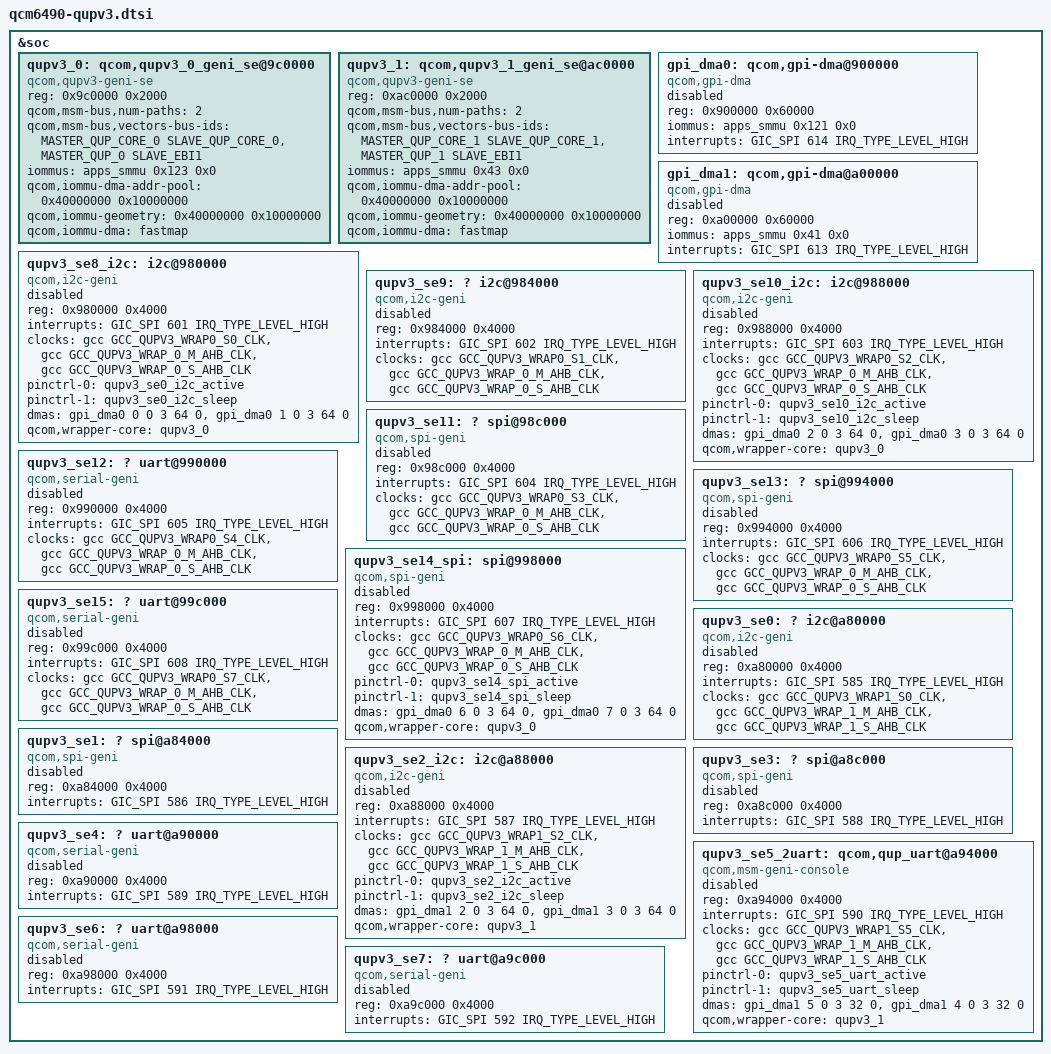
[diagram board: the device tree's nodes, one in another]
&soc {
	/* QUPv3 Serial Engine Instances mapping:
	 * - QUPv3_1 wrapper covers SE0..SE7
	 * - QUPv3_0 wrapper covers SE8..SE15
	 */

	/* QUPv3_0 wrapper instance (Serial Engines 8-15) */
	qupv3_0: qcom,qupv3_0_geni_se@9c0000 {
		compatible = "qcom,qupv3-geni-se";
		reg = <0x9c0000 0x2000>;
		qcom,msm-bus,num-paths = <2>;
		qcom,msm-bus,vectors-bus-ids =
			<MASTER_QUP_CORE_0 SLAVE_QUP_CORE_0>,
			<MASTER_QUP_0       SLAVE_EBI1>;
		iommus = <&apps_smmu 0x123 0x0>;
		qcom,iommu-dma-addr-pool = <0x40000000 0x10000000>;
		qcom,iommu-geometry    = <0x40000000 0x10000000>;
		qcom,iommu-dma         = "fastmap";
		status = "ok";
	};

	/* QUPv3_1 wrapper instance (Serial Engines 0-7) */
	qupv3_1: qcom,qupv3_1_geni_se@ac0000 {
		compatible = "qcom,qupv3-geni-se";
		reg = <0xac0000 0x2000>;
		qcom,msm-bus,num-paths = <2>;
		qcom,msm-bus,vectors-bus-ids =
			<MASTER_QUP_CORE_1 SLAVE_QUP_CORE_1>,
			<MASTER_QUP_1       SLAVE_EBI1>;
		iommus = <&apps_smmu 0x43 0x0>;
		qcom,iommu-dma-addr-pool = <0x40000000 0x10000000>;
		qcom,iommu-geometry    = <0x40000000 0x10000000>;
		qcom,iommu-dma         = "fastmap";
		status = "ok";
	};

	/* GPI DMA controllers for QUP (shared DMA engines) */
	gpi_dma0: qcom,gpi-dma@900000 {
		compatible = "qcom,gpi-dma";
		#dma-cells = <5>;
		reg = <0x900000 0x60000>;
		reg-names = "gpi-top";
		iommus = <&apps_smmu 0x121 0x0>;
		interrupts = <GIC_SPI 614 IRQ_TYPE_LEVEL_HIGH>;
		interrupt-names = "gpi";
		status = "disabled";
	};

	gpi_dma1: qcom,gpi-dma@a00000 {
		compatible = "qcom,gpi-dma";
		#dma-cells = <5>;
		reg = <0xa00000 0x60000>;
		reg-names = "gpi-top";
		iommus = <&apps_smmu 0x41 0x0>;
		interrupts = <GIC_SPI 613 IRQ_TYPE_LEVEL_HIGH>;
		interrupt-names = "gpi";
		status = "disabled";
	};

	/* QUPv3 Serial Engines (SE0..SE15) child nodes */
	qupv3_se8_i2c: i2c@980000 {
		compatible = "qcom,i2c-geni";
		reg = <0x980000 0x4000>;
		#address-cells = <1>;
		#size-cells = <0>;
		interrupts = <GIC_SPI 601 IRQ_TYPE_LEVEL_HIGH>;
		clock-names = "se-clk", "m-ahb", "s-ahb";
		clocks = <&gcc GCC_QUPV3_WRAP0_S0_CLK>,
			 <&gcc GCC_QUPV3_WRAP_0_M_AHB_CLK>,
			 <&gcc GCC_QUPV3_WRAP_0_S_AHB_CLK>;
		pinctrl-names = "default", "sleep";
		pinctrl-0 = <&qupv3_se0_i2c_active>;
		pinctrl-1 = <&qupv3_se0_i2c_sleep>;
		dmas = <&gpi_dma0 0 0 3 64 0>,
		       <&gpi_dma0 1 0 3 64 0>;
		dma-names = "tx", "rx";
		qcom,wrapper-core = <&qupv3_0>;
		status = "disabled";
	};

	qupv3_se9:? i2c@984000 {
		compatible = "qcom,i2c-geni";
		reg = <0x984000 0x4000>;
		#address-cells = <1>; #size-cells = <0>;
		interrupts = <GIC_SPI 602 IRQ_TYPE_LEVEL_HIGH>;
		clock-names = "se-clk", "m-ahb", "s-ahb";
		clocks = <&gcc GCC_QUPV3_WRAP0_S1_CLK>,
			 <&gcc GCC_QUPV3_WRAP_0_M_AHB_CLK>,
			 <&gcc GCC_QUPV3_WRAP_0_S_AHB_CLK>;
		... /* (pinctrl, DMA and wrapper-core similar to above) */
		status = "disabled";
	};

	qupv3_se10_i2c: i2c@988000 {
		compatible = "qcom,i2c-geni";
		reg = <0x988000 0x4000>;
		#address-cells = <1>; #size-cells = <0>;
		interrupts = <GIC_SPI 603 IRQ_TYPE_LEVEL_HIGH>;
		clock-names = "se-clk", "m-ahb", "s-ahb";
		clocks = <&gcc GCC_QUPV3_WRAP0_S2_CLK>,
			 <&gcc GCC_QUPV3_WRAP_0_M_AHB_CLK>,
			 <&gcc GCC_QUPV3_WRAP_0_S_AHB_CLK>;
		pinctrl-names = "default", "sleep";
		pinctrl-0 = <&qupv3_se10_i2c_active>;
		pinctrl-1 = <&qupv3_se10_i2c_sleep>;
		dmas = <&gpi_dma0 2 0 3 64 0>,
		       <&gpi_dma0 3 0 3 64 0>;
		dma-names = "tx", "rx";
		qcom,wrapper-core = <&qupv3_0>;
		status = "disabled";
	};

	qupv3_se11:? spi@98c000 {
		compatible = "qcom,spi-geni";
		reg = <0x98c000 0x4000>;
		#address-cells = <1>; #size-cells = <0>;
		interrupts = <GIC_SPI 604 IRQ_TYPE_LEVEL_HIGH>;
		clock-names = "se-clk", "m-ahb", "s-ahb";
		clocks = <&gcc GCC_QUPV3_WRAP0_S3_CLK>,
			 <&gcc GCC_QUPV3_WRAP_0_M_AHB_CLK>,
			 <&gcc GCC_QUPV3_WRAP_0_S_AHB_CLK>;
		... /* (pinctrl, DMA, wrapper-core properties) */
		status = "disabled";
	};

	qupv3_se12:? uart@990000 {
		compatible = "qcom,serial-geni";
		reg = <0x990000 0x4000>;
		#address-cells = <1>; #size-cells = <0>;
		interrupts = <GIC_SPI 605 IRQ_TYPE_LEVEL_HIGH>;
		clock-names = "se-clk", "m-ahb", "s-ahb";
		clocks = <&gcc GCC_QUPV3_WRAP0_S4_CLK>,
			 <&gcc GCC_QUPV3_WRAP_0_M_AHB_CLK>,
			 <&gcc GCC_QUPV3_WRAP_0_S_AHB_CLK>;
		... /* (pinctrl, DMA, wrapper-core) */
		status = "disabled";
	};

	qupv3_se13:? spi@994000 {
		compatible = "qcom,spi-geni";
		reg = <0x994000 0x4000>;
		#address-cells = <1>; #size-cells = <0>;
		interrupts = <GIC_SPI 606 IRQ_TYPE_LEVEL_HIGH>;
		clock-names = "se-clk", "m-ahb", "s-ahb";
		clocks = <&gcc GCC_QUPV3_WRAP0_S5_CLK>,
			 <&gcc GCC_QUPV3_WRAP_0_M_AHB_CLK>,
			 <&gcc GCC_QUPV3_WRAP_0_S_AHB_CLK>;
		... /* (pinctrl, DMA, wrapper-core) */
		status = "disabled";
	};

	qupv3_se14_spi: spi@998000 {
		compatible = "qcom,spi-geni";
		reg = <0x998000 0x4000>;
		#address-cells = <1>; #size-cells = <0>;
		interrupts = <GIC_SPI 607 IRQ_TYPE_LEVEL_HIGH>;
		clock-names = "se-clk", "m-ahb", "s-ahb";
		clocks = <&gcc GCC_QUPV3_WRAP0_S6_CLK>,
			 <&gcc GCC_QUPV3_WRAP_0_M_AHB_CLK>,
			 <&gcc GCC_QUPV3_WRAP_0_S_AHB_CLK>;
		pinctrl-names = "default", "sleep";
		pinctrl-0 = <&qupv3_se14_spi_active>;
		pinctrl-1 = <&qupv3_se14_spi_sleep>;
		dmas = <&gpi_dma0 6 0 3 64 0>,
		       <&gpi_dma0 7 0 3 64 0>;
		dma-names = "tx", "rx";
		qcom,wrapper-core = <&qupv3_0>;
		status = "disabled";
	};

	qupv3_se15:? uart@99c000 {
		compatible = "qcom,serial-geni";
		reg = <0x99c000 0x4000>;
		#address-cells = <1>; #size-cells = <0>;
		interrupts = <GIC_SPI 608 IRQ_TYPE_LEVEL_HIGH>;
		clock-names = "se-clk", "m-ahb", "s-ahb";
		clocks = <&gcc GCC_QUPV3_WRAP0_S7_CLK>,
			 <&gcc GCC_QUPV3_WRAP_0_M_AHB_CLK>,
			 <&gcc GCC_QUPV3_WRAP_0_S_AHB_CLK>;
		... /* (pinctrl, DMA, wrapper-core) */
		status = "disabled";
	};

	/* Serial Engines 0-7 on QUPv3_1 (addresses 0xa80000 - 0xa9c000) */
	qupv3_se0:? i2c@a80000 {
		compatible = "qcom,i2c-geni";
		reg = <0xa80000 0x4000>;
		#address-cells = <1>; #size-cells = <0>;
		interrupts = <GIC_SPI 585 IRQ_TYPE_LEVEL_HIGH>;
		clock-names = "se-clk", "m-ahb", "s-ahb";
		clocks = <&gcc GCC_QUPV3_WRAP1_S0_CLK>,
			 <&gcc GCC_QUPV3_WRAP_1_M_AHB_CLK>,
			 <&gcc GCC_QUPV3_WRAP_1_S_AHB_CLK>;
		... /* (pinctrl, DMA, wrapper-core similar, referencing &qupv3_1) */
		status = "disabled";
	};

	qupv3_se1:? spi@a84000 { /* SE1 */
		compatible = "qcom,spi-geni";
		reg = <0xa84000 0x4000>;
		interrupts = <GIC_SPI 586 IRQ_TYPE_LEVEL_HIGH>;
		... /* (other properties similar) */
		status = "disabled";
	};

	qupv3_se2_i2c: i2c@a88000 {
		compatible = "qcom,i2c-geni";
		reg = <0xa88000 0x4000>;
		interrupts = <GIC_SPI 587 IRQ_TYPE_LEVEL_HIGH>;
		clock-names = "se-clk", "m-ahb", "s-ahb";
		clocks = <&gcc GCC_QUPV3_WRAP1_S2_CLK>,
			 <&gcc GCC_QUPV3_WRAP_1_M_AHB_CLK>,
			 <&gcc GCC_QUPV3_WRAP_1_S_AHB_CLK>;
		pinctrl-names = "default", "sleep";
		pinctrl-0 = <&qupv3_se2_i2c_active>;
		pinctrl-1 = <&qupv3_se2_i2c_sleep>;
		dmas = <&gpi_dma1 2 0 3 64 0>,
		       <&gpi_dma1 3 0 3 64 0>;
		dma-names = "tx", "rx";
		qcom,wrapper-core = <&qupv3_1>;
		status = "disabled";
	};

	qupv3_se3:? spi@a8c000 {
		compatible = "qcom,spi-geni";
		reg = <0xa8c000 0x4000>;
		interrupts = <GIC_SPI 588 IRQ_TYPE_LEVEL_HIGH>;
		... /* similar properties */
		status = "disabled";
	};

	qupv3_se4:? uart@a90000 {
		compatible = "qcom,serial-geni";
		reg = <0xa90000 0x4000>;
		interrupts = <GIC_SPI 589 IRQ_TYPE_LEVEL_HIGH>;
		... /* similar */
		status = "disabled";
	};

	qupv3_se5_2uart: qcom,qup_uart@a94000 {
		compatible = "qcom,msm-geni-console";
		reg = <0xa94000 0x4000>;
		interrupts = <GIC_SPI 590 IRQ_TYPE_LEVEL_HIGH>;
		clock-names = "se-clk", "m-ahb", "s-ahb";
		clocks = <&gcc GCC_QUPV3_WRAP1_S5_CLK>,
			 <&gcc GCC_QUPV3_WRAP_1_M_AHB_CLK>,
			 <&gcc GCC_QUPV3_WRAP_1_S_AHB_CLK>;
		/* Note: Using "msm-geni-console" for primary UART (console) */
		pinctrl-names = "default", "sleep";
		pinctrl-0 = <&qupv3_se5_uart_active>;
		pinctrl-1 = <&qupv3_se5_uart_sleep>;
		dmas = <&gpi_dma1 5 0 3 32 0>,
		       <&gpi_dma1 4 0 3 32 0>;
		dma-names = "rx", "tx";
		qcom,wrapper-core = <&qupv3_1>;
		status = "disabled";
	};

	qupv3_se6:? uart@a98000 {
		compatible = "qcom,serial-geni";
		reg = <0xa98000 0x4000>;
		interrupts = <GIC_SPI 591 IRQ_TYPE_LEVEL_HIGH>;
		... /* similar */
		status = "disabled";
	};

	qupv3_se7:? uart@a9c000 {
		compatible = "qcom,serial-geni";
		reg = <0xa9c000 0x4000>;
		interrupts = <GIC_SPI 592 IRQ_TYPE_LEVEL_HIGH>;
		... /* similar */
		status = "disabled";
	};
};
